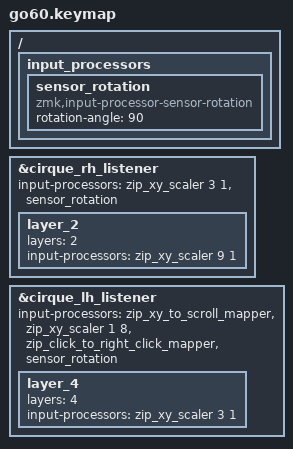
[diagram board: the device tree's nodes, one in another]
#define SELENIUM_KEYMAP_BINDINGS(LOUT1,  LROW1,  RROW1,  ROUT1, \
                                 LOUT2,  LROW2,  RROW2,  ROUT2, \
                                 LOUT3,  LROW3,  RROW3,  ROUT3, \
                                 LT1, LT2, LT3,  RT3, RT2, RT1) \
    &kp EQUAL &kp N1 &kp N2 &kp N3 &kp N4 &kp N5 &kp N6 &kp N7 &kp N8 &kp N9 &kp N0 &kp MINUS \
    LOUT1     LROW1                                                          RROW1  ROUT1     \
    LOUT2     LROW2                                                          RROW2  ROUT2     \
    LOUT3     LROW3                                                          RROW3  ROUT3     \
                     &none  &none  &none                &none  &none  &none                   \
                                LT1  LT2  LT3      RT3  RT2  RT1

#include <aekeynox/selenium.keymap>
#include <input/processors.dtsi>

#include <zephyr/dt-bindings/input/input-event-codes.h>
#include <dt-bindings/zmk/bt.h>
#include <dt-bindings/zmk/ext_power.h>
#include <dt-bindings/zmk/keys.h>
#include <dt-bindings/zmk/outputs.h>
#include <dt-bindings/zmk/rgb.h>
#include <dt-bindings/zmk/input_transform.h>
#include <dt-bindings/zmk/pointing.h>

&cirque_rh_listener {
    input-processors = <&zip_xy_scaler 3 1>, <&sensor_rotation>;
    layer_2 {
        layers = <2>;
        input-processors = <&zip_xy_scaler 9 1>;
    };
};

&cirque_lh_listener {
    input-processors = <&zip_xy_to_scroll_mapper>, <&zip_xy_scaler 1 8>, <&zip_click_to_right_click_mapper>, <&sensor_rotation>;
    layer_4 {
        layers = <4>;
        input-processors = <&zip_xy_scaler 3 1>;
    };
};


/ {
  input_processors {
    sensor_rotation: sensor_rotation {
      compatible = "zmk,input-processor-sensor-rotation";
      #input-processor-cells = <0>;
      rotation-angle = <90>;
    };
  };
};

#include <input/processors/sensor_rotation.dtsi>
